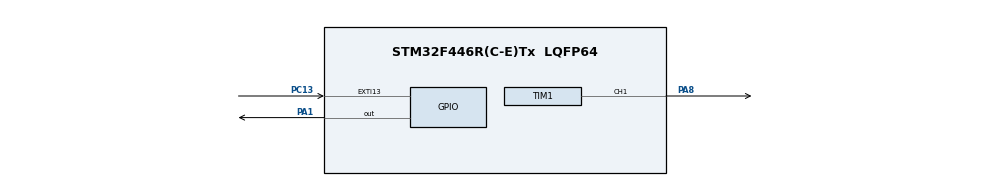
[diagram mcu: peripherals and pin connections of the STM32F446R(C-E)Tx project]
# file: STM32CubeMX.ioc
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Mcu.Family=STM32F4
Mcu.Name=STM32F446R(C-E)Tx
Mcu.Package=LQFP64
NVIC.EXTI15_10_IRQn=true\:0\:0\:false\:false\:true\:true\:true\:true
NVIC.PriorityGroup=NVIC_PRIORITYGROUP_4
PA1.Signal=GPIO_Output
PA8.Signal=S_TIM1_CH1
PC13.Signal=GPXTI13
PC14-OSC32_IN.Mode=LSE-External-Oscillator
PC14-OSC32_IN.Signal=RCC_OSC32_IN
PC15-OSC32_OUT.Mode=LSE-External-Oscillator
PC15-OSC32_OUT.Signal=RCC_OSC32_OUT
ProjectManager.HeapSize=0x200
ProjectManager.StackSize=0x400
ProjectManager.TargetToolchain=MDK-ARM V5
RCC.CortexFreq_Value=16000000
RCC.USBFreq_Value=96000000
RCC.VCOOutputFreq_Value=192000000
SH.S_TIM1_CH1.0=TIM1_CH1,PWM Generation1 CH1
TIM1.Channel-PWM\ Generation1\ CH1=TIM_CHANNEL_1
TIM1.Period=999
TIM1.Prescaler=15
board=custom

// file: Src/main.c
/* USER CODE BEGIN Header */
/**
  ******************************************************************************
  * @file           : main.c
  * @brief          : Main program body
  ******************************************************************************
  * @attention
  *
  * Copyright (c) 2026 STMicroelectronics.
  * All rights reserved.
  *
  * This software is licensed under terms that can be found in the LICENSE file
  * in the root directory of this software component.
  * If no LICENSE file comes with this software, it is provided AS-IS.
  *
  ******************************************************************************
  */
/* USER CODE END Header */
#include "main.h"

/* USER CODE BEGIN Includes */
#include <stdlib.h>
/* USER CODE END Includes */

TIM_HandleTypeDef htim1;

void SystemClock_Config(void);
static void MX_GPIO_Init(void);
static void MX_TIM1_Init(void);

/* USER CODE BEGIN 0 */

void play_tone(uint16_t freq)
{
	uint32_t timer_clk = 1000000;
	uint32_t period = timer_clk / freq;

	__HAL_TIM_SET_AUTORELOAD(&htim1, period);
	__HAL_TIM_SET_COMPARE(&htim1, TIM_CHANNEL_1, period / 2);
}

void HAL_GPIO_EXTI_Callback(uint16_t GPIO_PIN)
{
	if (GPIO_PIN == GPIO_PIN_13)
	{
		uint16_t freq = 500 + (rand() % 501);
		play_tone(freq);
		HAL_GPIO_TogglePin(GPIOA, GPIO_PIN_1);
	}
}
/* USER CODE END 0 */

int main(void)
{

  /* MCU Configuration--------------------------------------------------------*/

  /* Reset of all peripherals, Initializes the Flash interface and the Systick. */
  HAL_Init();

  /* Configure the system clock */
  SystemClock_Config();

  /* Initialize all configured peripherals */
  MX_GPIO_Init();
  MX_TIM1_Init();
  /* USER CODE BEGIN 2 */
	srand(HAL_GetTick());
	HAL_TIM_PWM_Start(&htim1, TIM_CHANNEL_1);
  /* USER CODE END 2 */

  /* Infinite loop */
  while (1)
  {

  }
}

void SystemClock_Config(void)
{
  RCC_OscInitTypeDef RCC_OscInitStruct = {0};
  RCC_ClkInitTypeDef RCC_ClkInitStruct = {0};

  /** Configure the main internal regulator output voltage
  */
  __HAL_RCC_PWR_CLK_ENABLE();
  __HAL_PWR_VOLTAGESCALING_CONFIG(PWR_REGULATOR_VOLTAGE_SCALE3);

  /** Initializes the RCC Oscillators according to the specified parameters
  * in the RCC_OscInitTypeDef structure.
  */
  RCC_OscInitStruct.OscillatorType = RCC_OSCILLATORTYPE_HSI;
  RCC_OscInitStruct.HSIState = RCC_HSI_ON;
  RCC_OscInitStruct.HSICalibrationValue = RCC_HSICALIBRATION_DEFAULT;
  RCC_OscInitStruct.PLL.PLLState = RCC_PLL_NONE;
  if (HAL_RCC_OscConfig(&RCC_OscInitStruct) != HAL_OK)
  {
    Error_Handler();
  }

  /** Initializes the CPU, AHB and APB buses clocks
  */
  RCC_ClkInitStruct.ClockType = RCC_CLOCKTYPE_HCLK|RCC_CLOCKTYPE_SYSCLK
                              |RCC_CLOCKTYPE_PCLK1|RCC_CLOCKTYPE_PCLK2;
  RCC_ClkInitStruct.SYSCLKSource = RCC_SYSCLKSOURCE_HSI;
  RCC_ClkInitStruct.AHBCLKDivider = RCC_SYSCLK_DIV1;
  RCC_ClkInitStruct.APB1CLKDivider = RCC_HCLK_DIV1;
  RCC_ClkInitStruct.APB2CLKDivider = RCC_HCLK_DIV1;

  if (HAL_RCC_ClockConfig(&RCC_ClkInitStruct, FLASH_LATENCY_0) != HAL_OK)
  {
    Error_Handler();
  }
}

static void MX_TIM1_Init(void)
{

  TIM_MasterConfigTypeDef sMasterConfig = {0};
  TIM_OC_InitTypeDef sConfigOC = {0};
  TIM_BreakDeadTimeConfigTypeDef sBreakDeadTimeConfig = {0};

  htim1.Instance = TIM1;
  htim1.Init.Prescaler = 15;
  htim1.Init.CounterMode = TIM_COUNTERMODE_UP;
  htim1.Init.Period = 999;
  htim1.Init.ClockDivision = TIM_CLOCKDIVISION_DIV1;
  htim1.Init.RepetitionCounter = 0;
  htim1.Init.AutoReloadPreload = TIM_AUTORELOAD_PRELOAD_DISABLE;
  if (HAL_TIM_PWM_Init(&htim1) != HAL_OK)
  {
    Error_Handler();
  }
  sMasterConfig.MasterOutputTrigger = TIM_TRGO_RESET;
  sMasterConfig.MasterSlaveMode = TIM_MASTERSLAVEMODE_DISABLE;
  if (HAL_TIMEx_MasterConfigSynchronization(&htim1, &sMasterConfig) != HAL_OK)
  {
    Error_Handler();
  }
  sConfigOC.OCMode = TIM_OCMODE_PWM1;
  sConfigOC.Pulse = 0;
  sConfigOC.OCPolarity = TIM_OCPOLARITY_HIGH;
  sConfigOC.OCNPolarity = TIM_OCNPOLARITY_HIGH;
  sConfigOC.OCFastMode = TIM_OCFAST_DISABLE;
  sConfigOC.OCIdleState = TIM_OCIDLESTATE_RESET;
  sConfigOC.OCNIdleState = TIM_OCNIDLESTATE_RESET;
  if (HAL_TIM_PWM_ConfigChannel(&htim1, &sConfigOC, TIM_CHANNEL_1) != HAL_OK)
  {
    Error_Handler();
  }
  sBreakDeadTimeConfig.OffStateRunMode = TIM_OSSR_DISABLE;
  sBreakDeadTimeConfig.OffStateIDLEMode = TIM_OSSI_DISABLE;
  sBreakDeadTimeConfig.LockLevel = TIM_LOCKLEVEL_OFF;
  sBreakDeadTimeConfig.DeadTime = 0;
  sBreakDeadTimeConfig.BreakState = TIM_BREAK_DISABLE;
  sBreakDeadTimeConfig.BreakPolarity = TIM_BREAKPOLARITY_HIGH;
  sBreakDeadTimeConfig.AutomaticOutput = TIM_AUTOMATICOUTPUT_DISABLE;
  if (HAL_TIMEx_ConfigBreakDeadTime(&htim1, &sBreakDeadTimeConfig) != HAL_OK)
  {
    Error_Handler();
  }
  HAL_TIM_MspPostInit(&htim1);

}

static void MX_GPIO_Init(void)
{
  GPIO_InitTypeDef GPIO_InitStruct = {0};

  /* GPIO Ports Clock Enable */
  __HAL_RCC_GPIOC_CLK_ENABLE();
  __HAL_RCC_GPIOA_CLK_ENABLE();

  /*Configure GPIO pin Output Level */
  HAL_GPIO_WritePin(GPIOA, GPIO_PIN_1, GPIO_PIN_RESET);

  /*Configure GPIO pin : PC13 */
  GPIO_InitStruct.Pin = GPIO_PIN_13;
  GPIO_InitStruct.Mode = GPIO_MODE_IT_RISING;
  GPIO_InitStruct.Pull = GPIO_NOPULL;
  HAL_GPIO_Init(GPIOC, &GPIO_InitStruct);

  /*Configure GPIO pin : PA1 */
  GPIO_InitStruct.Pin = GPIO_PIN_1;
  GPIO_InitStruct.Mode = GPIO_MODE_OUTPUT_PP;
  GPIO_InitStruct.Pull = GPIO_NOPULL;
  GPIO_InitStruct.Speed = GPIO_SPEED_FREQ_LOW;
  HAL_GPIO_Init(GPIOA, &GPIO_InitStruct);

  /* EXTI interrupt init*/
  HAL_NVIC_SetPriority(EXTI15_10_IRQn, 0, 0);
  HAL_NVIC_EnableIRQ(EXTI15_10_IRQn);

}

void Error_Handler(void)
{
  __disable_irq();
  while (1)
  {
  }
}
